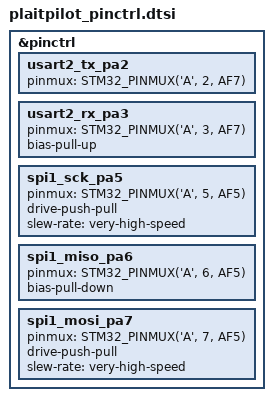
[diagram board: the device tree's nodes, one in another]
#include <zephyr/dt-bindings/pinctrl/stm32-pinctrl.h>

&pinctrl {
    usart2_tx_pa2: usart2_tx_pa2 {
        pinmux = <STM32_PINMUX('A', 2, AF7)>;
    };
    usart2_rx_pa3: usart2_rx_pa3 {
        pinmux = <STM32_PINMUX('A', 3, AF7)>;
        bias-pull-up;
    };

    spi1_sck_pa5: spi1_sck_pa5 {
        pinmux = <STM32_PINMUX('A', 5, AF5)>;
        drive-push-pull;
        slew-rate = "very-high-speed";
    };
    spi1_miso_pa6: spi1_miso_pa6 {
        pinmux = <STM32_PINMUX('A', 6, AF5)>;
        bias-pull-down;
    };
    spi1_mosi_pa7: spi1_mosi_pa7 {
        pinmux = <STM32_PINMUX('A', 7, AF5)>;
        drive-push-pull;
        slew-rate = "very-high-speed";
    };
};
